VERSION ""

NS_ :

BS_:

BU_: Orion

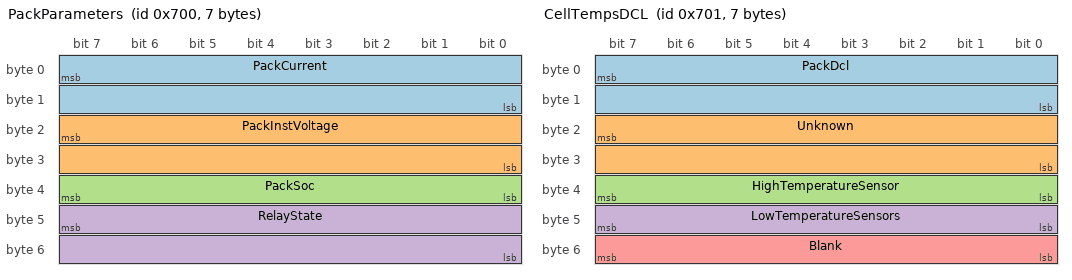
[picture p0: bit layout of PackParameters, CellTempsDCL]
BO_ 1792 PackParameters: 7 Orion
 SG_ PackCurrent : 7|16@0+ (1,0) [0|0] "" Vector__XXX
 SG_ PackInstVoltage : 23|16@0+ (1,0) [0|0] "" Vector__XXX
 SG_ PackSoc : 39|8@0+ (1,0) [0|0] "" Vector__XXX
 SG_ RelayState : 47|16@0+ (1,0) [0|0] "" Vector__XXX

BO_ 1793 CellTempsDCL: 7 Orion
 SG_ PackDcl : 7|16@0- (1,0) [0|0] "" Vector__XXX
 SG_ Unknown : 23|16@0- (1,0) [0|0] "" Vector__XXX
 SG_ HighTemperatureSensor : 39|8@0- (1,0) [0|0] "" Vector__XXX
 SG_ LowTemperatureSensors : 47|8@0- (1,0) [0|0] "" Vector__XXX
 SG_ Blank : 55|8@0- (1,0) [0|0] "" Vector__XXX

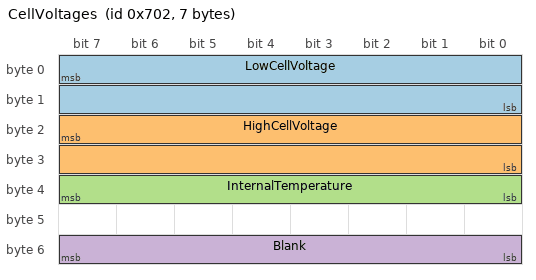
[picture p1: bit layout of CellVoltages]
BO_ 1794 CellVoltages: 7 Orion
 SG_ LowCellVoltage : 7|16@0+ (1,0) [0|0] "" Vector__XXX
 SG_ HighCellVoltage : 23|16@0+ (1,0) [0|0] "" Vector__XXX
 SG_ InternalTemperature : 39|8@0+ (1,0) [0|0] "" Vector__XXX
 SG_ Blank : 55|8@0+ (1,0) [0|0] "" Vector__XXX
